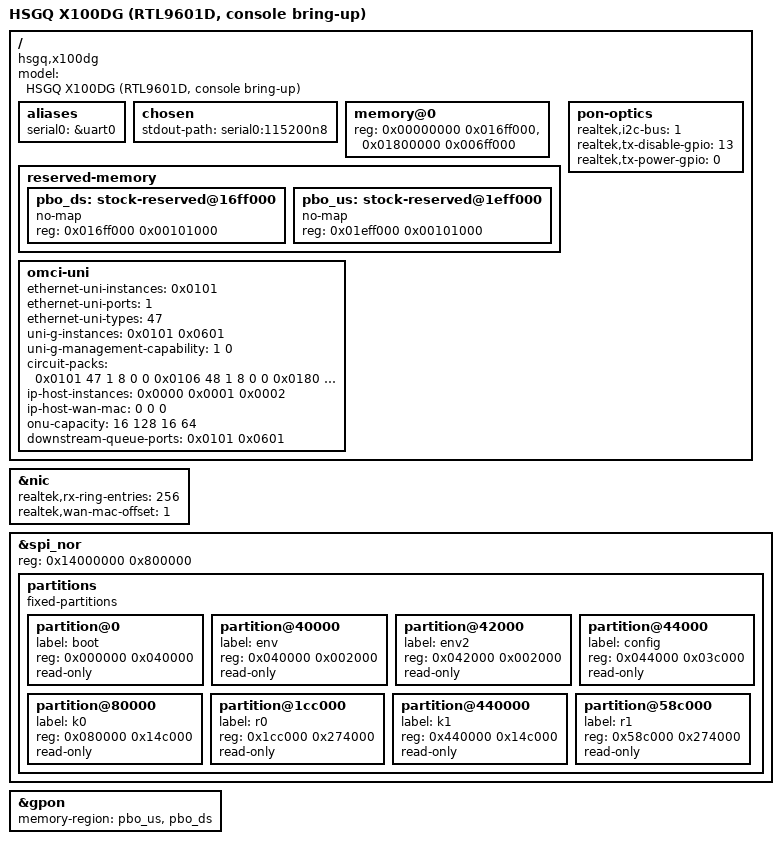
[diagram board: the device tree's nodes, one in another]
// SPDX-License-Identifier: GPL-2.0-or-later
/dts-v1/;

#include "rtl9602c.dtsi"

/* The RTL9601D runs the RTL9602C platform map: its own stock kernel (k1, Linux
 * 2.6.30.9) programs the same UART, INTC, timer, watchdog, UMSAR and NIC blocks
 * and never the PCIe host block, hence no "realtek,rtl9602c" root compatible
 * (pcie-luna keys on it).  dev/ONU-X100DG.md, 2026-09-30. */
/ {
	model = "HSGQ X100DG (RTL9601D, console bring-up)";
	compatible = "hsgq,x100dg", "realtek,rtl9601d";

	aliases {
		serial0 = &uart0;
	};

	chosen {
		stdout-path = "serial0:115200n8";
	};

	/* Own stock map: two spans; the hole after each is a PON packet pool. */
	memory@0 {
		device_type = "memory";
		reg = <0x00000000 0x016ff000>, <0x01800000 0x006ff000>;
	};

	reserved-memory {
		#address-cells = <1>;
		#size-cells = <1>;
		ranges;

		/* The two holes are stock's PON packet pools (its live PON-IP
		 * registers: MSTBASE_DS 0x016ff000, MSTBASE_US 0x01eff000). */
		pbo_ds: stock-reserved@16ff000 {
			no-map;
			reg = <0x016ff000 0x00101000>;
		};

		pbo_us: stock-reserved@1eff000 {
			no-map;
			reg = <0x01eff000 0x00101000>;
		};
	};

	/delete-node/ watchdog@18003260;

	/* Its BOSA is on I2C bus 1: stock loads europa_drv with I2C_PORT=1, and its
	 * live registers show bus 1's config (slave 0x54) and indirect block in use. */
	pon-optics {
		realtek,i2c-bus = <1>;
		realtek,tx-disable-gpio = <13>;	/* stock europa_drv TXDIS_PIN=13 */
		realtek,tx-power-gpio = <0>;	/* stock europa_drv TXPWR_PIN=0 */
	};

	/* The OMCI panel the OLT counts, from this unit's stock MIB (omci_panel.py
	 * over its gpon-oracle 2026-10-01): without it the OLT read 5 differences. */
	omci-uni {
		ethernet-uni-instances = /bits/ 16 <0x0101>;
		ethernet-uni-ports = /bits/ 8 <1>;
		ethernet-uni-types = /bits/ 8 <47>;
		uni-g-instances = /bits/ 16 <0x0101 0x0601>;
		uni-g-management-capability = /bits/ 8 <1 0>;
		circuit-packs = /bits/ 16 <
			0x0101 47 1 8 0 0
			0x0106 48 1 8 0 0
			0x0180 248 1 128 16 16>;
		ip-host-instances = /bits/ 16 <0x0000 0x0001 0x0002>;
		ip-host-wan-mac = /bits/ 8 <0 0 0>;
		onu-capacity = /bits/ 16 <16 128 16 64>;
		downstream-queue-ports = /bits/ 16 <0x0101 0x0601>;
	};
};

/* The GE jack is switch port 1: the vendor SDK gives the RTL9601D sub-types
 * port 0 = none, port 1 = GE (its HGU/SFU port table), the X111W's GE port. */

/* Stock's own ring: its boot prints RX[256,...]. 1024 buffers (~2.4 MB) do not
 * fit this board's 19 MB (2026-09-30: MemAvailable 2148 kB just before eth0). */
&nic {
	realtek,rx-ring-entries = <256>;
	realtek,wan-mac-offset = <1>;	/* stock nas0_0 is LAN+1 (98:c7:a4:29:a2:8f) */
};

/* Its own 8 MiB SPI-NOR, from its own U-Boot mtdparts, READ-ONLY through the
 * memory-mapped window: the provisioning reads this unit's identity and laser
 * calibration from "config", and nothing here can write the flash. */
&spi_nor {
	reg = <0x14000000 0x800000>;

	partitions {
		compatible = "fixed-partitions";
		#address-cells = <1>;
		#size-cells = <1>;

		partition@0 {
			label = "boot";
			reg = <0x000000 0x040000>;
			read-only;
		};
		partition@40000 {
			label = "env";
			reg = <0x040000 0x002000>;
			read-only;
		};
		partition@42000 {
			label = "env2";
			reg = <0x042000 0x002000>;
			read-only;
		};
		partition@44000 {
			label = "config";
			reg = <0x044000 0x03c000>;
			read-only;
		};
		partition@80000 {
			label = "k0";
			reg = <0x080000 0x14c000>;
			read-only;
		};
		partition@1cc000 {
			label = "r0";
			reg = <0x1cc000 0x274000>;
			read-only;
		};
		partition@440000 {
			label = "k1";
			reg = <0x440000 0x14c000>;
			read-only;
		};
		partition@58c000 {
			label = "r1";
			reg = <0x58c000 0x274000>;
			read-only;
		};
	};
};

/* US then DS, as luna_gpon reads them. */
&gpon {
	memory-region = <&pbo_us>, <&pbo_ds>;
};

/* The GPON stays ENABLED: the NIC's open re-runs the PON buffer init and the
 * switch fabric is programmed by this driver, so without it there is no LAN
 * (2026-09-30: Oops in rtl9602c_eth_open). A first boot holds the FSM at O1
 * with luna_gpon.gpon_hold=1 until this unit's own laser calibration (its
 * config partition, read above) is proven handed to the driver. */
